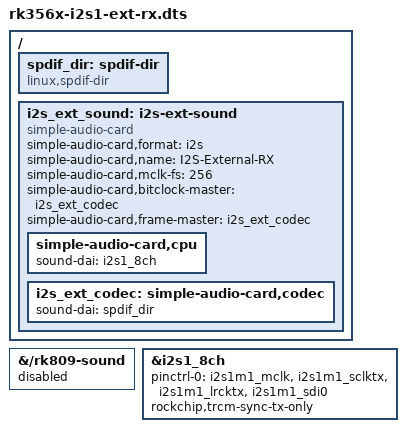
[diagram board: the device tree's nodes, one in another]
/dts-v1/;
/plugin/;

/*
 * Orange Pi 3B - I2S1 External RX (Slave) Overlay
 *
 * This overlay reconfigures I2S1 from the on-board RK809 codec (m0 pins)
 * to external GPIO pins (m1 mux) on the 40-pin header for board-to-board
 * I2S audio reception.
 *
 * WARNING: Enabling this overlay disables the RK809 headphone/speaker audio.
 *          HDMI audio (I2S0) remains unaffected.
 *
 * 40-pin header wiring (Slave RX board):
 *   Pin 11 - MCLK  (GPIO3_C6)  [optional, from Master]
 *   Pin 12 - SCLK  (GPIO3_C7)  <-- from Master Pin 12
 *   Pin 35 - LRCK  (GPIO3_D0)  <-- from Master Pin 35
 *   Pin 38 - SDI   (GPIO3_D2)  <-- from Master Pin 40 (SDO)
 *   Pin 39 - GND                <-- from Master GND
 */

/ {
	fragment@0 {
		target-path = "/rk809-sound";

		__overlay__ {
			status = "disabled";
		};
	};

	fragment@1 {
		target-path = "/";

		__overlay__ {
			spdif_dir: spdif-dir {
				compatible = "linux,spdif-dir";
				#sound-dai-cells = <0>;
				status = "okay";
			};

			i2s_ext_sound: i2s-ext-sound {
				compatible = "simple-audio-card";
				simple-audio-card,format = "i2s";
				simple-audio-card,name = "I2S-External-RX";
				simple-audio-card,mclk-fs = <256>;

				simple-audio-card,bitclock-master = <&i2s_ext_codec>;
				simple-audio-card,frame-master = <&i2s_ext_codec>;

				simple-audio-card,cpu {
					sound-dai = <&i2s1_8ch>;
				};

				i2s_ext_codec: simple-audio-card,codec {
					sound-dai = <&spdif_dir>;
				};
			};
		};
	};

	fragment@2 {
		target = <&i2s1_8ch>;

		__overlay__ {
			pinctrl-names = "default";
			pinctrl-0 = <&i2s1m1_mclk
				     &i2s1m1_sclktx
				     &i2s1m1_lrcktx
				     &i2s1m1_sdi0>;
			rockchip,trcm-sync-tx-only;
			status = "okay";
		};
	};
};
